# OCP_SOCKET_CM_CORE register map
Vendor: Texas Instruments
Peripheral module from a debugger description file (folder DM50x).
Registers are 32-bit, read-only, reset 0x40000301 unless marked. A register's access mark holds for its fields unless they carry their own. Offsets are as the file gives them; lines under a group give offsets from that group; [hi:lo] are bit positions; {n}, {i} and the like mark numbered series; 'fields as' and 'values as' point back to an identical list; <NAME> marks a mode.

## OCP_SOCKET_CM_CORE
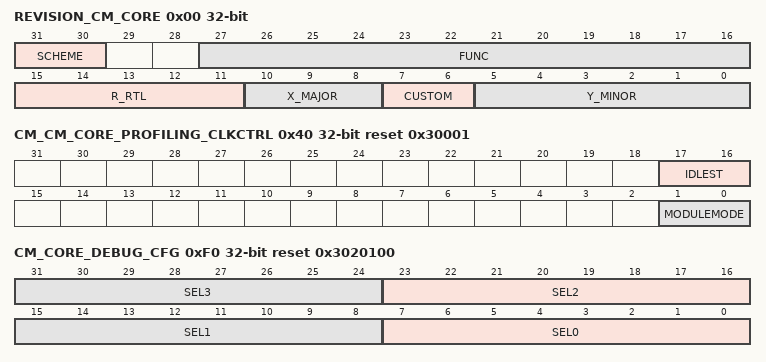
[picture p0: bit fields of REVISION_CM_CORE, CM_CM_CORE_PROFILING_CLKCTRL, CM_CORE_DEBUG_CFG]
0x00 REVISION_CM_CORE — This register contains the IP revision code for the CM_CORE part of the PRCM
  [31:30] SCHEME
  [27:16] FUNC — Function indicates a software compatible module family.
  [15:11] R_RTL — RTL Version (R)
  [10:8] X_MAJOR — Major Revision (X)
  [7:6] CUSTOM — Indicates a special version for a particular device.
    0=STANDARD (Non custom (standard) revision)
  [5:0] Y_MINOR — Minor Revision (Y)
    0=ES1 (ES1.0 and similar versions); 1=ES2 (ES2.0 and similar versions)
0x40 CM_CM_CORE_PROFILING_CLKCTRL access per field reset 0x30001 — This register manages the CM_CORE_PROFILING clocks. [warm reset insensitive]
  [17:16] IDLEST ro — Module idle status
    0=FUNC (Module is fully functional); 1=TRANS (Module is performing transition: wakeup, or sleep, or sleep abortion); 2=IDLE (Module is in Idle); 3=DISABLE (Module is disabled)
  [1:0] MODULEMODE rw — Control the way mandatory clocks are managed.
    0=DISABLED (Module is disabled by SW. OCP configuration port is not accessible.); 1=AUTO (Module is managed automatically by HW along with L3INSTR domain.)
0xF0 CM_CORE_DEBUG_CFG rw reset 0x3020100 — This register is used to configure the CM_CORE's 32-bit debug output. There is one 8-bit source select field for selecting from a shared set of 8-bit internal signal blocks per byte. The signals included in each block are specified in the PRCM integration specification. [warm reset insensitive]
  [8n+7:8n] SEL{n} (n=0..3) — Internal signal block select for debug word byte-{n}
